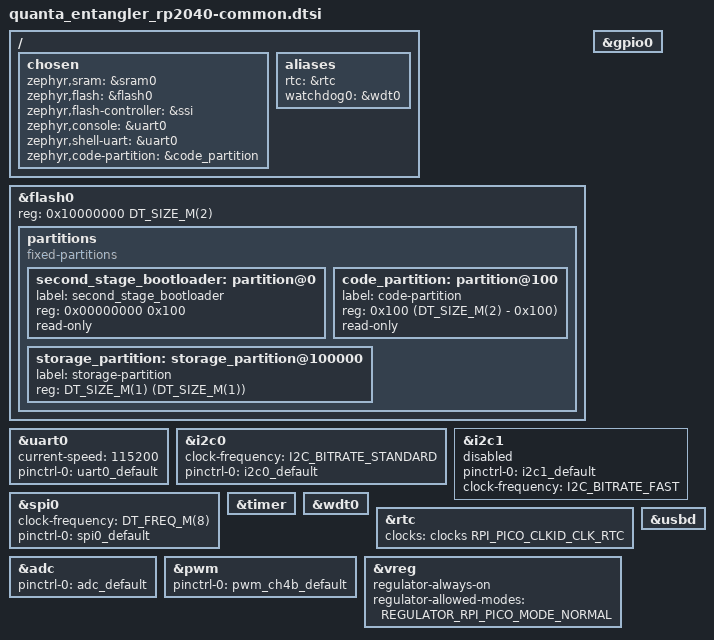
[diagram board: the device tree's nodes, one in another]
#include <freq.h>

#include <raspberrypi/rpi_pico/rp2040.dtsi>
#include "quanta_entangler_rp2040-pinctrl.dtsi"
#include <zephyr/dt-bindings/pwm/pwm.h>

#include <zephyr/dt-bindings/i2c/i2c.h>

/ {
	chosen {
		zephyr,sram = &sram0;
		zephyr,flash = &flash0;
		zephyr,flash-controller = &ssi;
		zephyr,console = &uart0;
		zephyr,shell-uart = &uart0;
		zephyr,code-partition = &code_partition;
	};

	aliases {
		rtc = &rtc;
		watchdog0 = &wdt0;
	};
};

&flash0 {
	reg = <0x10000000 DT_SIZE_M(2)>;

	partitions {
		compatible = "fixed-partitions";
		#address-cells = <1>;
		#size-cells = <1>;

		second_stage_bootloader: partition@0 {
			label = "second_stage_bootloader";
			reg = <0x00000000 0x100>;
			read-only;
		};

		code_partition: partition@100 {
			label = "code-partition";
			reg = <0x100 (DT_SIZE_M(2) - 0x100)>;
			read-only;
		};

		storage_partition: storage_partition@100000 {
			label = "storage-partition";
			reg = <DT_SIZE_M(1) (DT_SIZE_M(1))>;
		};
	};
};

&uart0 {
	current-speed = <115200>;
	status = "okay";
	pinctrl-0 = <&uart0_default>;
	pinctrl-names = "default";
};

&gpio0 {
	status = "okay";
};

&i2c0 {
	clock-frequency = <I2C_BITRATE_STANDARD>;
	status = "okay";
	pinctrl-0 = <&i2c0_default>;
	pinctrl-names = "default";
};

&i2c1 {
	pinctrl-0 = <&i2c1_default>;
	pinctrl-names = "default";
	status = "disabled";
	clock-frequency = <I2C_BITRATE_FAST>;
};

&spi0 {
	clock-frequency = <DT_FREQ_M(8)>;
	status = "okay";
	pinctrl-0 = <&spi0_default>;
	pinctrl-names = "default";
};

&timer {
	status = "okay";
};

&wdt0 {
	status = "okay";
};

&rtc {
	clocks = <&clocks RPI_PICO_CLKID_CLK_RTC>;
	status = "okay";
};

&adc {
	status = "okay";
	pinctrl-0 = <&adc_default>;
	pinctrl-names = "default";
};

zephyr_udc0: &usbd {
	status = "okay";
};

&pwm {
	pinctrl-0 = <&pwm_ch4b_default>;
	pinctrl-names = "default";
};

&vreg {
	regulator-always-on;
	regulator-allowed-modes = <REGULATOR_RPI_PICO_MODE_NORMAL>;
};

pico_spi: &spi0 {};
pico_i2c0: &i2c0 {};
pico_i2c1: &i2c1 {};
pico_serial: &uart0 {};
